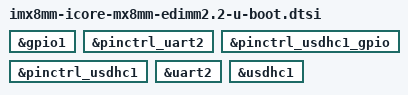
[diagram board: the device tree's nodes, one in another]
// SPDX-License-Identifier: (GPL-2.0+ OR MIT)
/*
 * Copyright (c) 2020 Engicam srl
 * Copyright (c) 2020 Amarula Solutions(India)
 */

#include "imx8mm-icore-mx8mm-u-boot.dtsi"

&gpio1 {
	bootph-pre-ram;
};

&pinctrl_uart2 {
	bootph-pre-ram;
};

&pinctrl_usdhc1_gpio {
	bootph-pre-ram;
};

&pinctrl_usdhc1 {
	bootph-pre-ram;
};

&uart2 {
	bootph-pre-ram;
};

&usdhc1 {
	bootph-pre-ram;
};
